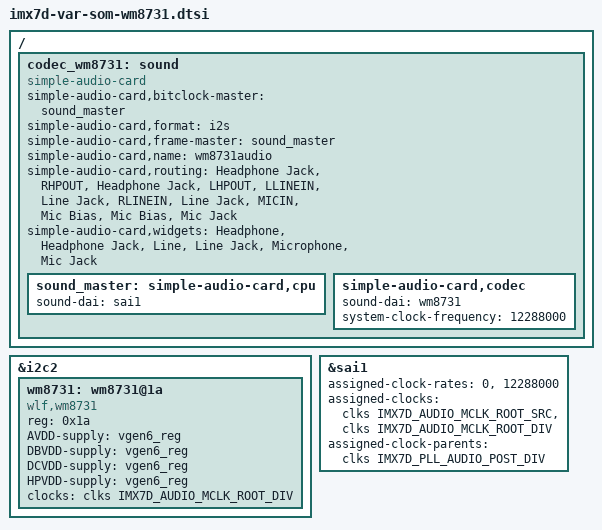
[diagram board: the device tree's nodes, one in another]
// SPDX-License-Identifier: (GPL-2.0+ OR MIT)
/*
 * Common dtsi for WM8731 support on Variscite VAR-SOM-MX7
 *
 * Link: https://variscite.com/system-on-module-som/i-mx-7/var-som-mx7/
 *
 * Copyright (C) 2026 Variscite Ltd. - https://www.variscite.com/
 *
 */

/delete-node/ &codec_wm8904;
/delete-node/ &wm8904;

/ {
	codec_wm8731: sound {
		compatible = "simple-audio-card";
		simple-audio-card,bitclock-master = <&sound_master>;
		simple-audio-card,format = "i2s";
		simple-audio-card,frame-master = <&sound_master>;
		simple-audio-card,name = "wm8731audio";
		simple-audio-card,routing =
			"Headphone Jack", "RHPOUT",
			"Headphone Jack", "LHPOUT",
			"LLINEIN", "Line Jack",
			"RLINEIN", "Line Jack",
			"MICIN", "Mic Bias",
			"Mic Bias", "Mic Jack";
		simple-audio-card,widgets =
			"Headphone", "Headphone Jack",
			"Line", "Line Jack",
			"Microphone", "Mic Jack";

		sound_master: simple-audio-card,cpu {
			sound-dai = <&sai1>;
		};

		simple-audio-card,codec {
			sound-dai = <&wm8731>;
			system-clock-frequency = <12288000>;
		};
	};
};

&i2c2 {
	wm8731: wm8731@1a {
		compatible = "wlf,wm8731";
		reg = <0x1a>;
		#sound-dai-cells = <0>;
		AVDD-supply = <&vgen6_reg>;
		DBVDD-supply = <&vgen6_reg>;
		DCVDD-supply = <&vgen6_reg>;
		HPVDD-supply = <&vgen6_reg>;
		clocks = <&clks IMX7D_AUDIO_MCLK_ROOT_DIV>;
		clock-names = "mclk";
	};
};

&sai1 {
	assigned-clock-rates = <0>, <36864000>;
	assigned-clocks = <&clks IMX7D_AUDIO_MCLK_ROOT_SRC>,
			  <&clks IMX7D_AUDIO_MCLK_ROOT_DIV>;
	assigned-clock-parents = <&clks IMX7D_PLL_AUDIO_POST_DIV>;
	assigned-clock-rates = <0>, <12288000>;
	/delete-property/ fsl,sai-mclk-direction-output;
};
